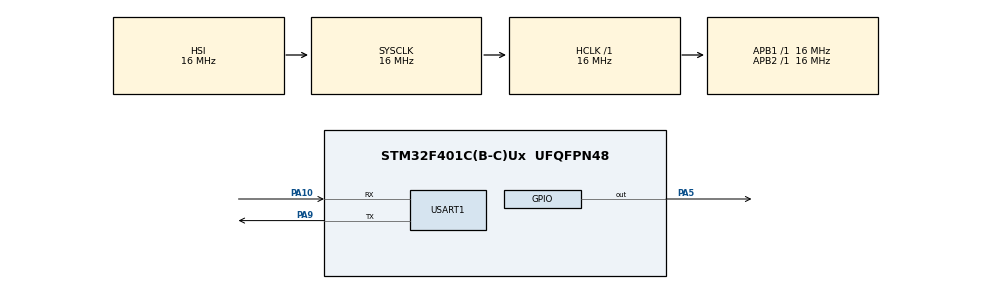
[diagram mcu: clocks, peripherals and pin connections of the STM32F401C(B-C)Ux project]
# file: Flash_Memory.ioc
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Mcu.Family=STM32F4
Mcu.Name=STM32F401C(B-C)Ux
Mcu.Package=UFQFPN48
NVIC.PriorityGroup=NVIC_PRIORITYGROUP_4
PA10.Mode=Asynchronous
PA10.Signal=USART1_RX
PA5.Signal=GPIO_Output
PA9.Mode=Asynchronous
PA9.Signal=USART1_TX
ProjectManager.HeapSize=0x200
ProjectManager.StackSize=0x400
ProjectManager.TargetToolchain=STM32CubeIDE
RCC.AHBFreq_Value=16000000
RCC.APB1Freq_Value=16000000
RCC.APB2Freq_Value=16000000
RCC.CortexFreq_Value=16000000
RCC.HSE_VALUE=25000000
RCC.HSI_VALUE=16000000
RCC.LSE_VALUE=32768
RCC.SYSCLKFreq_VALUE=16000000
RCC.VCOOutputFreq_Value=192000000
USART1.VirtualMode=VM_ASYNC
board=custom

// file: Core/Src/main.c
/* USER CODE BEGIN Header */
/**
  ******************************************************************************
  * @file           : main.c
  * @brief          : Main program body
  ******************************************************************************
  * @attention
  *
  * Copyright (c) 2025 STMicroelectronics.
  * All rights reserved.
  *
  * This software is licensed under terms that can be found in the LICENSE file
  * in the root directory of this software component.
  * If no LICENSE file comes with this software, it is provided AS-IS.
  *
  ******************************************************************************
  */
/* USER CODE END Header */
#include "main.h"
#include <stdio.h>  // For sprintf
/* USER CODE BEGIN Includes */
#define FLASH_SECTOR_ADDRESS  0x08020000  // Start of Sector 5 (Example)
#define MAX_WRITE_CYCLES      100000      // Simulating max write cycles before corruption

// Write data to the specified flash address
void Flash_Write(uint32_t address, uint32_t data) {
    // Unlock Flash
    HAL_FLASH_Unlock();

    // Erase Sector
    FLASH_EraseInitTypeDef eraseInitStruct;
    uint32_t sectorError;
    eraseInitStruct.TypeErase = FLASH_TYPEERASE_SECTORS;
    eraseInitStruct.VoltageRange = FLASH_VOLTAGE_RANGE_3;
    eraseInitStruct.Sector = FLASH_SECTOR_5;
    eraseInitStruct.NbSectors = 1;

    if (HAL_FLASHEx_Erase(&eraseInitStruct, &sectorError) != HAL_OK) {
        // Error handling
        while (1);
    }

    // Write Data
    if (HAL_FLASH_Program(FLASH_TYPEPROGRAM_WORD, address, data) != HAL_OK) {
        // Error handling
        while (1);
    }

    // Lock Flash
    HAL_FLASH_Lock();
}

// Corrected Flash Read: Now it returns the value stored at the address
uint32_t Flash_Read(uint32_t address) {
    return *(volatile uint32_t*)address;  // Dereference to read the value at the address
}

/* USER CODE END Includes */

UART_HandleTypeDef huart1;

void SystemClock_Config(void);
static void MX_GPIO_Init(void);
static void MX_USART1_UART_Init(void);

// Function to create a delay for a specified number of microseconds
void delay_us(uint32_t us) {
    uint32_t count;

    // Loop for each microsecond
    while (us--) {
        // Each loop iteration takes ~1 clock cycle
        for (count = 0; count < (SystemCoreClock / 1000000); count++) {
            __NOP(); // No operation, just burn some cycles
        }
    }
}
int main(void)
{
	HAL_Init();
	    SystemClock_Config();
	    MX_GPIO_Init();
	    MX_USART1_UART_Init();

	    uint32_t writeData = 0x12345678;
	    uint32_t corruptionThreshold = MAX_WRITE_CYCLES; // Set the threshold for write cycles

	    // Loop that will simulate writing to the same memory address
	    for (uint32_t cycle = 0; cycle < corruptionThreshold; cycle++) {
	        Flash_Write(FLASH_SECTOR_ADDRESS, writeData);

	        // Simulate some changing data (could be any pattern or changing value)
	        writeData += 0x100;  // Change data slightly to simulate write activity

	        // Optionally, you can periodically read and transmit the value over UART
	        uint32_t readData = Flash_Read(FLASH_SECTOR_ADDRESS);

	        // Print the value to UART in a hexadecimal format
	        char dataString[9];  // 8 characters for hex + null terminator
	        sprintf(dataString, "Cycle: %lu, Data: 0x%08X\r\n", cycle, readData);
	        HAL_UART_Transmit(&huart1, (uint8_t*)dataString, strlen(dataString), 20);

	        delay_us(1);

	    }

	    // Once we've exceeded the write cycles, check for potential memory corruption
	    uint32_t readDataAfter = Flash_Read(FLASH_SECTOR_ADDRESS);
	    char corruptionMsg[50];

	    // If the readData doesn't match expected, print memory corruption message
	    if (readDataAfter != 0x12345678) {
	        sprintf(corruptionMsg, "Memory Corrupted! Last read: 0x%08X\r\n", readDataAfter);
	        HAL_UART_Transmit(&huart1, (uint8_t*)corruptionMsg, strlen(corruptionMsg), 20);
	    } else {
	        HAL_UART_Transmit(&huart1, (uint8_t*)"Memory is fine.\r\n", 17, 20);
	    }

	    // Infinite loop after the simulation
	    while (1) {
	        HAL_Delay(1000);
	    }
}

void SystemClock_Config(void)
{
  RCC_OscInitTypeDef RCC_OscInitStruct = {0};
  RCC_ClkInitTypeDef RCC_ClkInitStruct = {0};

  /** Configure the main internal regulator output voltage
  */
  __HAL_RCC_PWR_CLK_ENABLE();
  __HAL_PWR_VOLTAGESCALING_CONFIG(PWR_REGULATOR_VOLTAGE_SCALE2);

  /** Initializes the RCC Oscillators according to the specified parameters
  * in the RCC_OscInitTypeDef structure.
  */
  RCC_OscInitStruct.OscillatorType = RCC_OSCILLATORTYPE_HSI;
  RCC_OscInitStruct.HSIState = RCC_HSI_ON;
  RCC_OscInitStruct.HSICalibrationValue = RCC_HSICALIBRATION_DEFAULT;
  RCC_OscInitStruct.PLL.PLLState = RCC_PLL_NONE;
  if (HAL_RCC_OscConfig(&RCC_OscInitStruct) != HAL_OK)
  {
    Error_Handler();
  }

  /** Initializes the CPU, AHB and APB buses clocks
  */
  RCC_ClkInitStruct.ClockType = RCC_CLOCKTYPE_HCLK|RCC_CLOCKTYPE_SYSCLK
                              |RCC_CLOCKTYPE_PCLK1|RCC_CLOCKTYPE_PCLK2;
  RCC_ClkInitStruct.SYSCLKSource = RCC_SYSCLKSOURCE_HSI;
  RCC_ClkInitStruct.AHBCLKDivider = RCC_SYSCLK_DIV1;
  RCC_ClkInitStruct.APB1CLKDivider = RCC_HCLK_DIV1;
  RCC_ClkInitStruct.APB2CLKDivider = RCC_HCLK_DIV1;

  if (HAL_RCC_ClockConfig(&RCC_ClkInitStruct, FLASH_LATENCY_0) != HAL_OK)
  {
    Error_Handler();
  }
}

static void MX_USART1_UART_Init(void)
{

  huart1.Instance = USART1;
  huart1.Init.BaudRate = 115200;
  huart1.Init.WordLength = UART_WORDLENGTH_8B;
  huart1.Init.StopBits = UART_STOPBITS_1;
  huart1.Init.Parity = UART_PARITY_NONE;
  huart1.Init.Mode = UART_MODE_TX_RX;
  huart1.Init.HwFlowCtl = UART_HWCONTROL_NONE;
  huart1.Init.OverSampling = UART_OVERSAMPLING_16;
  if (HAL_UART_Init(&huart1) != HAL_OK)
  {
    Error_Handler();
  }

}

static void MX_GPIO_Init(void)
{
  GPIO_InitTypeDef GPIO_InitStruct = {0};

  /* GPIO Ports Clock Enable */
  __HAL_RCC_GPIOA_CLK_ENABLE();

  /*Configure GPIO pin Output Level */
  HAL_GPIO_WritePin(GPIOA, GPIO_PIN_5, GPIO_PIN_RESET);

  /*Configure GPIO pin : PA5 */
  GPIO_InitStruct.Pin = GPIO_PIN_5;
  GPIO_InitStruct.Mode = GPIO_MODE_OUTPUT_PP;
  GPIO_InitStruct.Pull = GPIO_NOPULL;
  GPIO_InitStruct.Speed = GPIO_SPEED_FREQ_LOW;
  HAL_GPIO_Init(GPIOA, &GPIO_InitStruct);

}

void Error_Handler(void)
{
  __disable_irq();
  while (1)
  {
  }
}
